# PIC32CZ4010CA90208 device description
Architecture: CORTEX-M7; Family: PIC32C; Series: PIC32CZCA90
Registers are 32-bit, read-write, reset 0x0 unless marked. A register's access mark holds for its fields unless they carry their own. Offsets are from the block's base; [hi:lo] are bit positions; {n}, {i} and the like mark numbered series; 'fields as' and 'values as' point back to an identical list.

## PRM — Boot ROM Controller
Instances: PRM 0x44080000
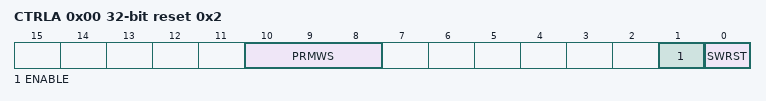
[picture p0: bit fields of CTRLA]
0x00 CTRLA reset 0x2 — CONTROL A REGISTER
  [10:8] PRMWS — ROM ACCESS TIME WAIT STATE
  [1] ENABLE — ENABLE BIT
  [0] SWRST — SOFTWARE RESET BIT

## RSTC — Reset Controller
Instances: RSTC 0x44030000
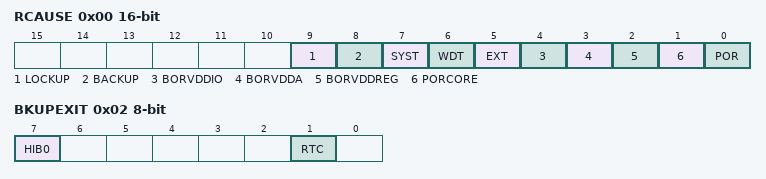
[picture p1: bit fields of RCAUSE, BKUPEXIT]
0x00 RCAUSE 16-bit ro reset not defined — Reset Cause
  [9] LOCKUP — Lockup Reset
  [8] BACKUP — Backup Reset
  [7] SYST — System Reset Request
  [6] WDT — Watchdog Reset
  [5] EXT — External Reset
  [4] BORVDDIO — Brown Out VDDIO Detector Reset
  [3] BORVDDA — Brown Out VDDA Detector Reset
  [2] BORVDDREG — Brown Out VDDREG Detector Reset
  [1] PORCORE — Brown Out CORE Detector Reset
  [0] POR — Power On Reset
0x02 BKUPEXIT 8-bit ro — Backup Exit Source. Implemented only if RSTC_BACKUP_IMPLEMENTED=1
  [7] HIB0 — Hibernate
  [1] RTC — Real Timer Counter Interrupt
0x04 DBGCTRL — Debug Control
  [0] LCKUPDIS — Lockup Disable

## SQI_DESCRIPTOR — Polaris Serial Quad Interface SIB
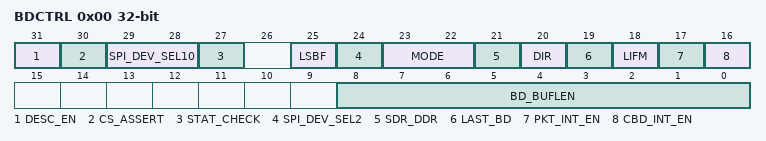
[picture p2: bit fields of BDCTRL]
0x00 BDCTRL reset not defined — Buffer Descriptor Control Register
  [31] DESC_EN — Descriptor Enable
  [30] CS_ASSERT — Chip Select Assert/Deassert
  [29:28] SPI_DEV_SEL10 — SPI Device Select bits 1:0
  [27] STAT_CHECK — Status Check
  [25] LSBF — Data format on SPI Data Lanes
  [24] SPI_DEV_SEL2 — SPI Device Select bit 2
  [23:22] MODE — Based on the mode, the controller has to transmit or receive the data in one or two or 4 lanes
  [21] SDR_DDR — SDR or DDR mode
  [20] DIR — Direction of data transfer.
  [19] LAST_BD — Last Buffer Descriptors.
  [18] LIFM — Indicates last data of the packet.
  [17] PKT_INT_EN — Generate Interrupt after processing the current buffer descriptor, if it is the end of the packet.
  [16] CBD_INT_EN — Generate Interrupt after processing the current buffer descriptor
  [8:0] BD_BUFLEN — Buffer Descriptor Length
0x04 BDSTATUS reset not defined — Buffer Descriptor Status Register
0x08 BDADDR reset not defined — Buffer Descriptor Address Register
0x0C BDNXTPTR reset not defined — Buffer Descriptor Next Pointer Register

## SysTick — System timer
Instances: SysTick 0xE000E010
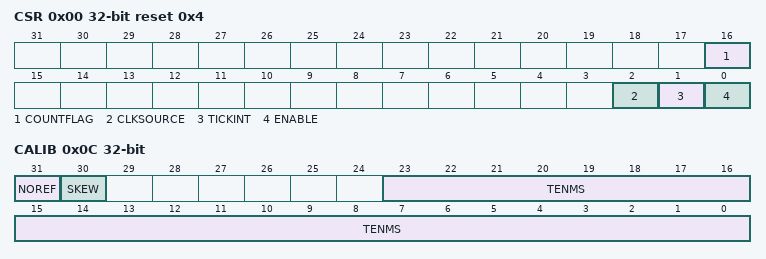
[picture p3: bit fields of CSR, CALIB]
0x00 CSR reset 0x4 — SysTick Control and Status Register
  [16] COUNTFLAG — Timer counted to 0 since last read of register
  [2] CLKSOURCE — Clock Source 0=external, 1=processor
    0=External clock; 1=Processor clock
  [1] TICKINT — SysTick Exception Request Enable
    0=Counting down to 0 does not assert the SysTick exception request; 1=Counting down to 0 asserts the SysTick exception request
  [0] ENABLE — SysTick Counter Enable
    0=Counter disabled; 1=Counter enabled
0x04 RVR reset not defined — SysTick Reload Value Register
  [23:0] RELOAD — Value to load into the SysTick Current Value Register when the counter reaches 0
0x08 CVR reset not defined — SysTick Current Value Register
  [23:0] CURRENT — Current value at the time the register is accessed
0x0C CALIB ro — SysTick Calibration Value Register
  [31] NOREF — No Separate Reference Clock
    0=The reference clock is provided; 1=The reference clock is not provided
  [30] SKEW — TENMS is rounded from non-integer ratio
    0=10ms calibration value is exact; 1=10ms calibration value is inexact, because of the clock frequency
  [23:0] TENMS — Reload value to use for 10ms timing

## TPI — Trace Port Interface Register
Instances: TPI 0xE0040000
0x00 SSPSR ro reset not defined — Supported Parallel Port Size Register
0x04 CSPSR reset not defined — Current Parallel Port Size Register
0x10 ACPR reset not defined — Asynchronous Clock Prescaler Register
  [12:0] PRESCALER
0xF0 SPPR reset not defined — Selected Pin Protocol Register
  [1:0] TXMODE
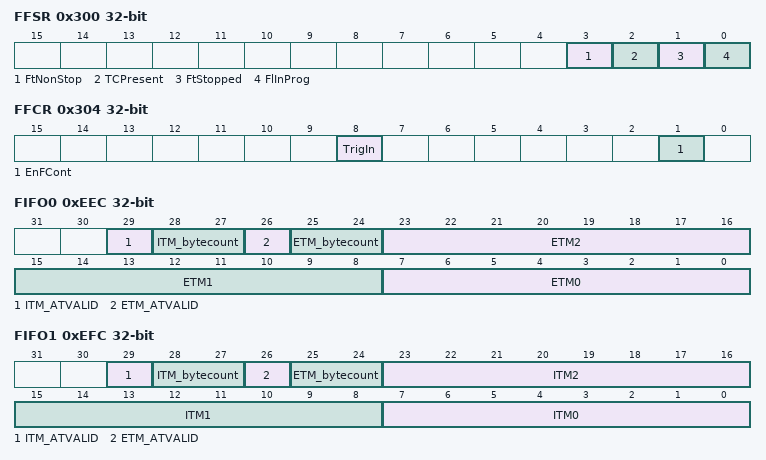
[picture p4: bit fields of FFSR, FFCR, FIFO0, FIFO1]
0x300 FFSR ro reset not defined — Formatter and Flush Status Register
  [3] FtNonStop, [2] TCPresent, [1] FtStopped, [0] FlInProg
0x304 FFCR reset not defined — Formatter and Flush Control Register
  [8] TrigIn, [1] EnFCont
0x308 FSCR ro reset not defined — Formatter Synchronization Counter Register
0xEE8 TRIGGER ro reset not defined
  [0] TRIGGER
0xEEC FIFO0 ro reset not defined — Integration ETM Data
  [29] ITM_ATVALID, [28:27] ITM_bytecount, [26] ETM_ATVALID, [25:24] ETM_bytecount, [23:16] ETM2, [15:8] ETM1, [7:0] ETM0
0xEF0 ITATBCTR2 ro reset not defined
  [0] ATREADY
0xEF8 ITATBCTR0 ro reset not defined
  [0] ATREADY
0xEFC FIFO1 ro reset not defined — Integration ITM Data
  [29] ITM_ATVALID, [28:27] ITM_bytecount, [26] ETM_ATVALID, [25:24] ETM_bytecount, [23:16] ITM2, [15:8] ITM1, [7:0] ITM0
0xF00 ITCTRL reset not defined — Integration Mode Control
  [0] Mode
0xFA0 CLAIMSET reset not defined (atomic set) — Claim tag set
0xFA4 CLAIMCLR reset not defined (atomic clear) — Claim tag clear
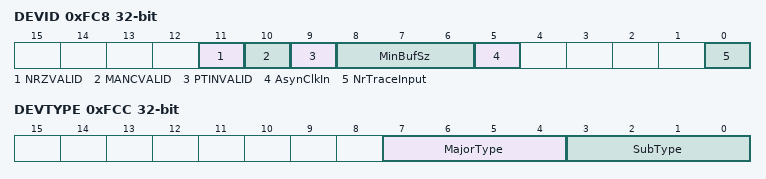
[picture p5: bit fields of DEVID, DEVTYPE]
0xFC8 DEVID ro reset not defined — TPIU_DEVID
  [11] NRZVALID, [10] MANCVALID, [9] PTINVALID, [8:6] MinBufSz, [5] AsynClkIn, [0] NrTraceInput
0xFCC DEVTYPE ro reset not defined — TPIU_DEVTYPE
  [7:4] MajorType, [3:0] SubType

## TRAM — TrustRAM
Instances: TRAM 0x44824000
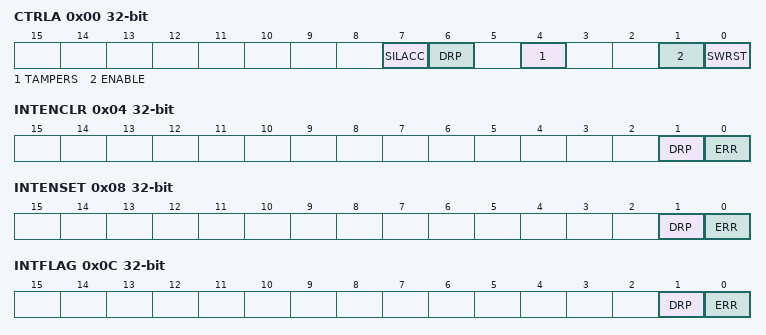
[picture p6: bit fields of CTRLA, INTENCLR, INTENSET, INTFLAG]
0x00 CTRLA — Control
  [7] SILACC — Silent Access
  [6] DRP — Data Remanence Prevention
  [4] TAMPERS — Tamper Erase
  [1] ENABLE
  [0] SWRST — Software Reset
0x04 INTENCLR (atomic clear) — Interrupt Enable Clear
  [1] DRP — Data Remanence Prevention Ended Interrupt Enable
  [0] ERR — TrustRAM Readout Error Interrupt Enable
0x08 INTENSET (atomic set) — Interrupt Enable Set
  fields as INTENCLR
0x0C INTFLAG (atomic clear) — Interrupt Flag Status and Clear
  [1] DRP — Data Remanence Prevention Ended
  [0] ERR — TrustRAM Readout Error
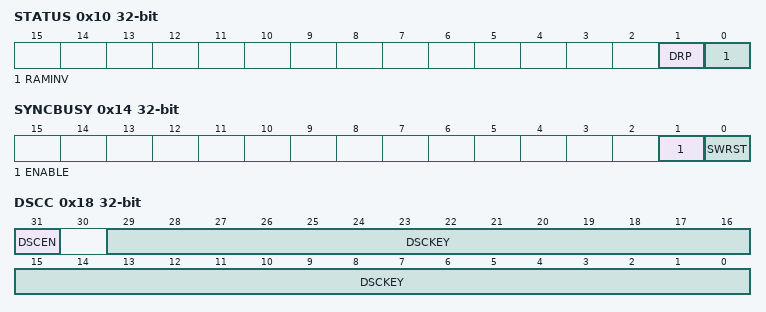
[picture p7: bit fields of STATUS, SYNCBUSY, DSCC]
0x10 STATUS ro
  [1] DRP — Data Remanence Prevention Ongoing
  [0] RAMINV — RAM Inversion Bit
0x14 SYNCBUSY ro — Synchronization Busy Status
  [1] ENABLE — Enable Busy
  [0] SWRST — Software Reset Busy
0x18 DSCC wo — Data Scramble Control
  [31] DSCEN — Data Scramble Enable
  [29:0] DSCKEY — Data Scramble Key
0x1C PERMW wo — Permutation Write
  [2:0] DATA — Permutation Scrambler Data Input
0x20 PERMR ro — Permutation Read
  [2:0] DATA — Permutation Scrambler Data Output
{0x1000+4i} RAM[{i}] (i=0..2047) — TrustRAM
  [31:0] DATA — Trust RAM Data

## TRNG — True Random Generator
Instances: TRNG 0x44870000
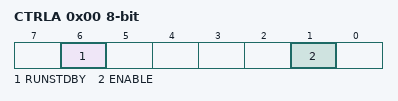
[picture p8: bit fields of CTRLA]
0x00 CTRLA 8-bit — Control A
  [6] RUNSTDBY — Run in Standby
  [1] ENABLE
0x04 EVCTRL 8-bit — Event Control
  [0] DATARDYEO — Data Ready Event Output
0x08 INTENCLR 8-bit (atomic clear) — Interrupt Enable Clear
  [0] DATARDY — Data Ready Interrupt Enable
0x09 INTENSET 8-bit (atomic set) — Interrupt Enable Set
  [0] DATARDY — Data Ready Interrupt Enable
0x0A INTFLAG 8-bit (atomic clear) — Interrupt Flag Status and Clear
  [0] DATARDY — Data Ready Interrupt Flag
0x20 DATA ro reset not defined — Output Data

## WDT — Watchdog Timer
Instances: WDT 0x44070000
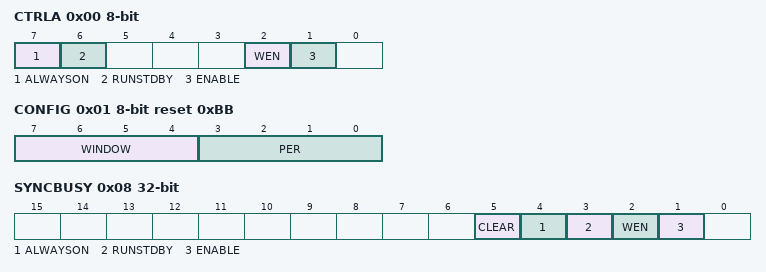
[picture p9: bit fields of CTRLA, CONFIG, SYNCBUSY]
0x00 CTRLA 8-bit (WSYNC) — Control
  [7] ALWAYSON
  [6] RUNSTDBY — Run During Standby
  [2] WEN — Watchdog Timer Window Mode Enable
  [1] ENABLE
0x01 CONFIG 8-bit reset 0xBB — Configuration
  [7:4] WINDOW — Window Mode Time-Out Period
    0=CYC8 (8 clock cycles); 1=CYC16 (16 clock cycles); 2=CYC32 (32 clock cycles); 3=CYC64 (64 clock cycles); 4=CYC128 (128 clock cycles); 5=CYC256 (256 clock cycles); 6=CYC512 (512 clock cycles); 7=CYC1024 (1024 clock cycles); 8=CYC2048 (2048 clock cycles); 9=CYC4096 (4096 clock cycles); 10=CYC8192 (8192 clock cycles); 11=CYC16384 (16384 clock cycles)
  [3:0] PER — Time-Out Period
    values as WINDOW
0x02 EWCTRL 8-bit reset 0xB — Early Warning Interrupt Control
  [3:0] EWOFFSET — Early Warning Interrupt Time Offset
    values as CONFIG.WINDOW
0x04 INTENCLR 8-bit (atomic clear) — Interrupt Enable Clear
  [0] EW — Early Warning Interrupt Enable
0x05 INTENSET 8-bit (atomic set) — Interrupt Enable Set
  [0] EW — Early Warning Interrupt Enable
0x06 INTFLAG 8-bit (atomic clear) — Interrupt Flag Status and Clear
  [0] EW — Early Warning
0x08 SYNCBUSY ro — Synchronization Busy
  [5] CLEAR — Clear Synchronization Busy
  [4] ALWAYSON — Always-On Synchronization Busy
  [3] RUNSTDBY — Run During Standby Synchronization Busy
  [2] WEN — Window Enable Synchronization Busy
  [1] ENABLE — Enable Synchronization Busy
0x0C CLEAR 8-bit wo (WSYNC)
  [7:0] CLEAR — Watchdog Clear
    165=KEY (Clear Key)

## Notices in the file
Copyright (c) 2021 Microchip Technology Inc.
SPDX-License-Identifier: Apache-2.0
Licensed under the Apache License, Version 2.0 (the "License");
you may not use this file except in compliance with the License.
You may obtain a copy of the License at
http://www.apache.org/licenses/LICENSE-2.0
Unless required by applicable law or agreed to in writing, software
distributed under the License is distributed on an "AS IS" BASIS,
WITHOUT WARRANTIES OR CONDITIONS OF ANY KIND, either express or implied.
See the License for the specific language governing permissions and
limitations under the License.
